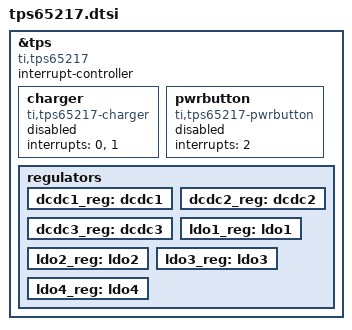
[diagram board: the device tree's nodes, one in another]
// SPDX-License-Identifier: GPL-2.0-only
/*
 * Copyright (C) 2012 Texas Instruments Incorporated - http://www.ti.com/
 */

/*
 * Integrated Power Management Chip
 * http://www.ti.com/lit/ds/symlink/tps65217.pdf
 */

&tps {
	compatible = "ti,tps65217";
	interrupt-controller;
	#interrupt-cells = <1>;

	charger {
		compatible = "ti,tps65217-charger";
		interrupts = <0>, <1>;
		interrupt-names = "USB", "AC";
		status = "disabled";
	};

	pwrbutton {
		compatible = "ti,tps65217-pwrbutton";
		interrupts = <2>;
		status = "disabled";
	};

	regulators {
		dcdc1_reg: dcdc1 {
		};

		dcdc2_reg: dcdc2 {
		};

		dcdc3_reg: dcdc3 {
		};

		ldo1_reg: ldo1 {
		};

		ldo2_reg: ldo2 {
		};

		ldo3_reg: ldo3 {
		};

		ldo4_reg: ldo4 {
		};
	};
};
